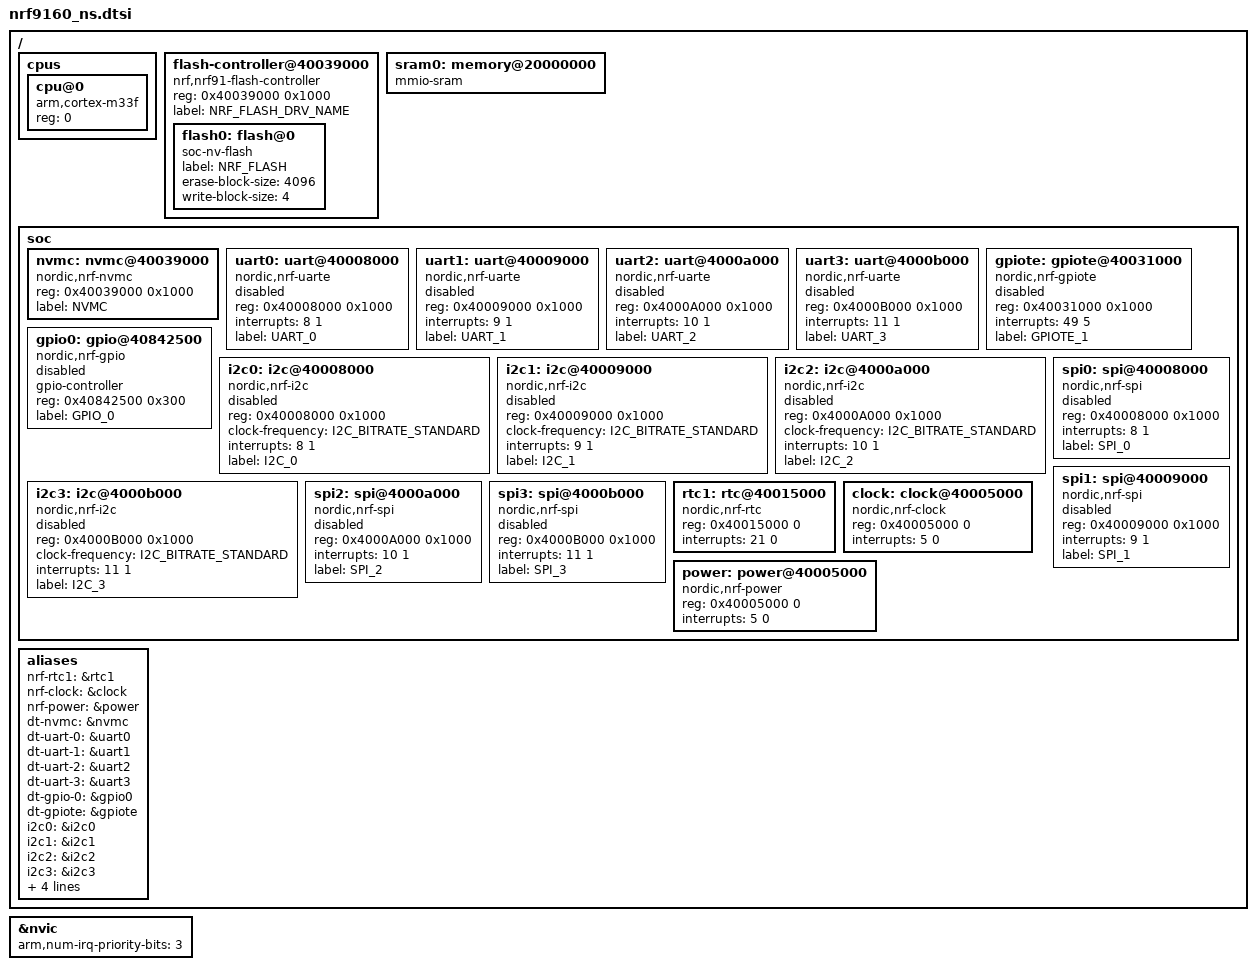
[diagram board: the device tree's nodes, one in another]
#include <arm/armv8-m.dtsi>
#include <dt-bindings/gpio/gpio.h>
#include <dt-bindings/i2c/i2c.h>
/ {
	cpus {
		#address-cells = <1>;
		#size-cells = <0>;

		cpu@0 {
			device_type = "cpu";
			compatible = "arm,cortex-m33f";
			reg = <0>;
		};
	};

	flash-controller@40039000 {
			compatible = "nrf,nrf91-flash-controller";
			reg = <0x40039000 0x1000>;

			#address-cells = <1>;
			#size-cells = <1>;

			label="NRF_FLASH_DRV_NAME";

			flash0: flash@0 {
				compatible = "soc-nv-flash";
				label = "NRF_FLASH";
				erase-block-size = <4096>;
				write-block-size = <4>;
			};
	};

	sram0: memory@20000000 {
		device_type = "memory";
		compatible = "mmio-sram";
	};

	soc {
		nvmc: nvmc@40039000 {
			compatible = "nordic,nrf-nvmc";
			reg = <0x40039000 0x1000>;
			status = "ok";
			label = "NVMC";
		};

		uart0: uart@40008000 {
			compatible = "nordic,nrf-uarte";
			reg = <0x40008000 0x1000>;
			interrupts = <8 1>;
			status = "disabled";
			label = "UART_0";
		};

		uart1: uart@40009000 {
			compatible = "nordic,nrf-uarte";
			reg = <0x40009000 0x1000>;
			interrupts = <9 1>;
			status = "disabled";
			label = "UART_1";
		};

		uart2: uart@4000a000 {
			compatible = "nordic,nrf-uarte";
			reg = <0x4000A000 0x1000>;
			interrupts = <10 1>;
			status = "disabled";
			label = "UART_2";
		};

		uart3: uart@4000b000 {
			compatible = "nordic,nrf-uarte";
			reg = <0x4000B000 0x1000>;
			interrupts = <11 1>;
			status = "disabled";
			label = "UART_3";
		};

		gpiote: gpiote@40031000 {
			compatible = "nordic,nrf-gpiote";
			reg = <0x40031000 0x1000>;
			interrupts = <49 5>;
			interrupt-names = "gpiote";
			status = "disabled";
			label = "GPIOTE_1";
		};

		gpio0: gpio@40842500 {
			compatible = "nordic,nrf-gpio";
			gpio-controller;
			reg = <0x40842500 0x300>;
			#gpio-cells = <2>;
			label = "GPIO_0";
			status = "disabled";
		};

		i2c0: i2c@40008000 {
			compatible = "nordic,nrf-i2c";
			#address-cells = <1>;
			#size-cells = <0>;
			reg = <0x40008000 0x1000>;
			clock-frequency = <I2C_BITRATE_STANDARD>;
			interrupts = <8 1>;
			status = "disabled";
			label = "I2C_0";
		};

		i2c1: i2c@40009000 {
			compatible = "nordic,nrf-i2c";
			#address-cells = <1>;
			#size-cells = <0>;
			reg = <0x40009000 0x1000>;
			clock-frequency = <I2C_BITRATE_STANDARD>;
			interrupts = <9 1>;
			status = "disabled";
			label = "I2C_1";
		};

		i2c2: i2c@4000a000 {
			compatible = "nordic,nrf-i2c";
			#address-cells = <1>;
			#size-cells = <0>;
			reg = <0x4000A000 0x1000>;
			clock-frequency = <I2C_BITRATE_STANDARD>;
			interrupts = <10 1>;
			status = "disabled";
			label = "I2C_2";
		};

		i2c3: i2c@4000b000 {
			compatible = "nordic,nrf-i2c";
			#address-cells = <1>;
			#size-cells = <0>;
			reg = <0x4000B000 0x1000>;
			clock-frequency = <I2C_BITRATE_STANDARD>;
			interrupts = <11 1>;
			status = "disabled";
			label = "I2C_3";
		};

		spi0: spi@40008000 {
			compatible = "nordic,nrf-spi";
			#address-cells = <1>;
			#size-cells = <0>;
			reg = <0x40008000 0x1000>;
			interrupts = <8 1>;
			status = "disabled";
			label = "SPI_0";
		};

		spi1: spi@40009000 {
			compatible = "nordic,nrf-spi";
			#address-cells = <1>;
			#size-cells = <0>;
			reg = <0x40009000 0x1000>;
			interrupts = <9 1>;
			status = "disabled";
			label = "SPI_1";
		};

		spi2: spi@4000a000 {
			compatible = "nordic,nrf-spi";
			#address-cells = <1>;
			#size-cells = <0>;
			reg = <0x4000A000 0x1000>;
			interrupts = <10 1>;
			status = "disabled";
			label = "SPI_2";
		};

		spi3: spi@4000b000 {
			compatible = "nordic,nrf-spi";
			#address-cells = <1>;
			#size-cells = <0>;
			reg = <0x4000B000 0x1000>;
			interrupts = <11 1>;
			status = "disabled";
			label = "SPI_3";
		};

		rtc1: rtc@40015000 {
			compatible = "nordic,nrf-rtc";
			reg = <0x40015000 0>;
			interrupts = <21 0>;
			status = "ok";
		};

		clock: clock@40005000 {
			compatible = "nordic,nrf-clock";
			reg = <0x40005000 0>;
			interrupts = <5 0>;
			status = "ok";
		};

		power: power@40005000 {
			compatible = "nordic,nrf-power";
			reg = <0x40005000 0>;
			interrupts = <5 0>;
			status = "ok";
		};
	};
	aliases {
		nrf-rtc1 = &rtc1;
		nrf-clock = &clock;
		nrf-power = &power;
		dt-nvmc = &nvmc;
		dt-uart-0 = &uart0;
		dt-uart-1 = &uart1;
		dt-uart-2 = &uart2;
		dt-uart-3 = &uart3;
		dt-gpio-0 = &gpio0;
		dt-gpiote = &gpiote;
		i2c0 = &i2c0;
		i2c1 = &i2c1;
		i2c2 = &i2c2;
		i2c3 = &i2c3;
		spi0 = &spi0;
		spi1 = &spi1;
		spi2 = &spi2;
		spi3 = &spi3;
	};
};

&nvic {
	arm,num-irq-priority-bits = <3>;
};
